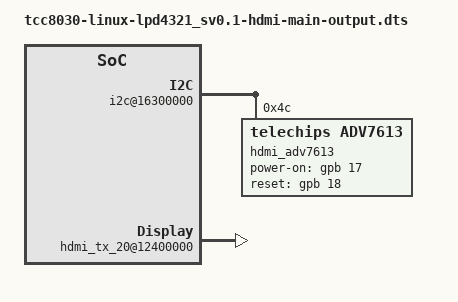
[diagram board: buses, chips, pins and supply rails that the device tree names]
// SPDX-License-Identifier: (GPL-2.0-or-later OR MIT)
/*
 * Copyright (C) Telechips Inc.
 */

#include "tcc8030-linux-lpd4321_sv0.1.dts"

/ {
	/* Here is hdmi override. */

	i2c@16300000 {
		hdmi_adv7613 {
			compatible = "telechips,adv7613";
			reg=<0x4C>;
			main-slave = <0x4C>;
			cec-slave = <0x40>;
			info-slave = <0x3E>;
			dpll-slave = <0x26>;
			ksv-slave = <0x32>;
			edid-slave = <0x36>;
			hdmi-slave = <0x34>;
			cp-slave = <0x22>;
			lvds-slave = <0x60>;
			power-on-gpios = <&gpb 17 0>;		// LCD_ON
			reset-gpios = <&gpb 18 0>;		// LCD_RST
		};
	};

	hdmi_tx_20@12400000 {
		status = "okay";
		hdmi_ref_src_clock = <0>; // 0 XIN, 1 X-TAL, 2 PERI, 3, PMU XIN
		hdmi_phy_type = <0>; // 0 8031

		/* DDC */
		hdmi_i2c_port_disable = <0>;

		/* Source Product Description */
		product_description = "TCC8031_ivi";
	};

	/* gmac
	 * gmac1_rxer	: gpc-14
	 * gmac1_rxdv	: gpc-8
	 * gmac1_txer	: gpc-15
	 */
	gmac@11b00000 {
		status = "disable";
	};

	/* uart7_rtscts	: gpc-8, gpc-9 */
	/* i2c14_bus	: gpc-14, gpc-15 */

	/* output starter */
	output_starter {
		status = "disable";
		compatible = "telechips,tcc-output-starter";
	};

};
